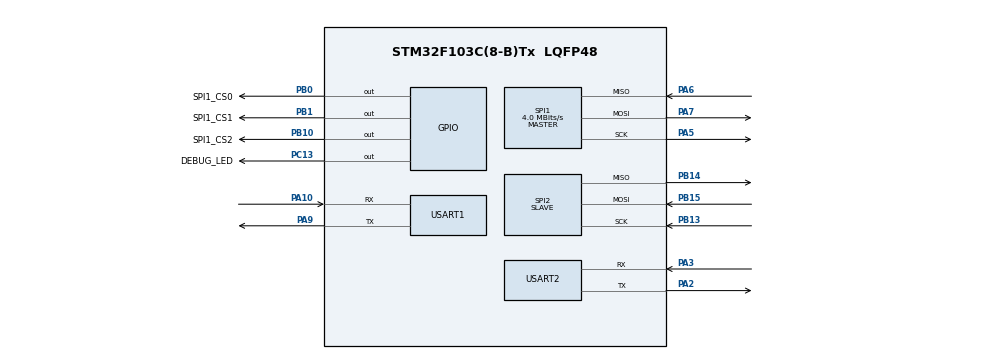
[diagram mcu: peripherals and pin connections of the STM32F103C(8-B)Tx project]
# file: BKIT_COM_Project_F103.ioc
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Mcu.Family=STM32F1
Mcu.Name=STM32F103C(8-B)Tx
Mcu.Package=LQFP48
NVIC.PriorityGroup=NVIC_PRIORITYGROUP_4
NVIC.TIM2_IRQn=true\:0\:0\:false\:false\:true\:true\:true\:true
NVIC.USART1_IRQn=true\:0\:0\:false\:false\:true\:true\:true\:true
NVIC.USART2_IRQn=true\:0\:0\:false\:false\:true\:true\:true\:true
PA10.Mode=Asynchronous
PA10.Signal=USART1_RX
PA13.Mode=Serial_Wire
PA13.Signal=SYS_JTMS-SWDIO
PA14.Mode=Serial_Wire
PA14.Signal=SYS_JTCK-SWCLK
PA2.Mode=Asynchronous
PA2.Signal=USART2_TX
PA3.Mode=Asynchronous
PA3.Signal=USART2_RX
PA5.Mode=Full_Duplex_Master
PA5.Signal=SPI1_SCK
PA6.Mode=Full_Duplex_Master
PA6.Signal=SPI1_MISO
PA7.Mode=Full_Duplex_Master
PA7.Signal=SPI1_MOSI
PA9.Mode=Asynchronous
PA9.Signal=USART1_TX
PB0.GPIO_Label=SPI1_CS0
PB0.PinState=GPIO_PIN_SET
PB0.Signal=GPIO_Output
PB1.GPIO_Label=SPI1_CS1
PB1.PinState=GPIO_PIN_SET
PB1.Signal=GPIO_Output
PB10.GPIO_Label=SPI1_CS2
PB10.PinState=GPIO_PIN_SET
PB10.Signal=GPIO_Output
PB13.Mode=Full_Duplex_Slave
PB13.Signal=SPI2_SCK
PB14.Mode=Full_Duplex_Slave
PB14.Signal=SPI2_MISO
PB15.Mode=Full_Duplex_Slave
PB15.Signal=SPI2_MOSI
PC13-TAMPER-RTC.GPIO_Label=DEBUG_LED
PC13-TAMPER-RTC.Signal=GPIO_Output
ProjectManager.HeapSize=0x200
ProjectManager.StackSize=0x400
ProjectManager.TargetToolchain=STM32CubeIDE
RCC.APB1Freq_Value=8000000
RCC.APB2Freq_Value=8000000
SPI1.CalculateBaudRate=4.0 MBits/s
SPI1.Direction=SPI_DIRECTION_2LINES
SPI1.Mode=SPI_MODE_MASTER
SPI1.VirtualType=VM_MASTER
SPI2.Direction=SPI_DIRECTION_2LINES
SPI2.Mode=SPI_MODE_SLAVE
SPI2.VirtualType=VM_SLAVE
TIM2.AutoReloadPreload=TIM_AUTORELOAD_PRELOAD_ENABLE
TIM2.Period=1
TIM2.Prescaler=8000-1
USART1.VirtualMode=VM_ASYNC
USART2.VirtualMode=VM_ASYNC
VP_CRC_VS_CRC.Mode=CRC_Activate
VP_TIM2_VS_ClockSourceINT.Mode=Internal
board=custom

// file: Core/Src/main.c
/* USER CODE BEGIN Header */
/**
  ******************************************************************************
  * @file           : main.c
  * @brief          : Main program body
  ******************************************************************************
  * @attention
  *
  * Copyright (c) 2025 STMicroelectronics.
  * All rights reserved.
  *
  * This software is licensed under terms that can be found in the LICENSE file
  * in the root directory of this software component.
  * If no LICENSE file comes with this software, it is provided AS-IS.
  *
  ******************************************************************************
  */
/* USER CODE END Header */
#include "main.h"
#include "crc.h"
#include "spi.h"
#include "tim.h"
#include "usart.h"
#include "gpio.h"

/* USER CODE BEGIN Includes */
#include "timer.h"
#include "Serial_Debug.h"
#include "Application_Layer.h"
#include "data_type.pb.h"
/* USER CODE END Includes */

void SystemClock_Config(void);

int main(void)
{

  /* MCU Configuration--------------------------------------------------------*/

  /* Reset of all peripherals, Initializes the Flash interface and the Systick. */
  HAL_Init();

  /* Configure the system clock */
  SystemClock_Config();

  /* Initialize all configured peripherals */
  MX_GPIO_Init();
  MX_TIM2_Init();
  MX_USART1_UART_Init();
  MX_SPI1_Init();
  MX_SPI2_Init();
  MX_USART2_UART_Init();
  MX_CRC_Init();

  /* Infinite loop */
  /* USER CODE BEGIN WHILE */
  sensor_data_t data;
//  data.data = 1000;
//  data.function_code = 0x01;
//  data.sensor_id = 12345;
  	data.data = 5;
    data.function_code = 0x05;
    data.sensor_id = 5;

  uint8_t function_code = 0x01;
  while (1)
  {
    /* USER CODE END WHILE */

    /* USER CODE BEGIN 3 */
//	  HAL_UART_Transmit(&huart2, (uint8_t*)"hehe", 4, 1000);
	  BKIT_ReceiveMessage(&data);
	  HAL_Delay(5000);
  }
  /* USER CODE END 3 */
}

void SystemClock_Config(void)
{
  RCC_OscInitTypeDef RCC_OscInitStruct = {0};
  RCC_ClkInitTypeDef RCC_ClkInitStruct = {0};

  /** Initializes the RCC Oscillators according to the specified parameters
  * in the RCC_OscInitTypeDef structure.
  */
  RCC_OscInitStruct.OscillatorType = RCC_OSCILLATORTYPE_HSI;
  RCC_OscInitStruct.HSIState = RCC_HSI_ON;
  RCC_OscInitStruct.HSICalibrationValue = RCC_HSICALIBRATION_DEFAULT;
  RCC_OscInitStruct.PLL.PLLState = RCC_PLL_NONE;
  if (HAL_RCC_OscConfig(&RCC_OscInitStruct) != HAL_OK)
  {
    Error_Handler();
  }

  /** Initializes the CPU, AHB and APB buses clocks
  */
  RCC_ClkInitStruct.ClockType = RCC_CLOCKTYPE_HCLK|RCC_CLOCKTYPE_SYSCLK
                              |RCC_CLOCKTYPE_PCLK1|RCC_CLOCKTYPE_PCLK2;
  RCC_ClkInitStruct.SYSCLKSource = RCC_SYSCLKSOURCE_HSI;
  RCC_ClkInitStruct.AHBCLKDivider = RCC_SYSCLK_DIV1;
  RCC_ClkInitStruct.APB1CLKDivider = RCC_HCLK_DIV1;
  RCC_ClkInitStruct.APB2CLKDivider = RCC_HCLK_DIV1;

  if (HAL_RCC_ClockConfig(&RCC_ClkInitStruct, FLASH_LATENCY_0) != HAL_OK)
  {
    Error_Handler();
  }
}

void Error_Handler(void)
{
  __disable_irq();
  while (1)
  {
  }
}
